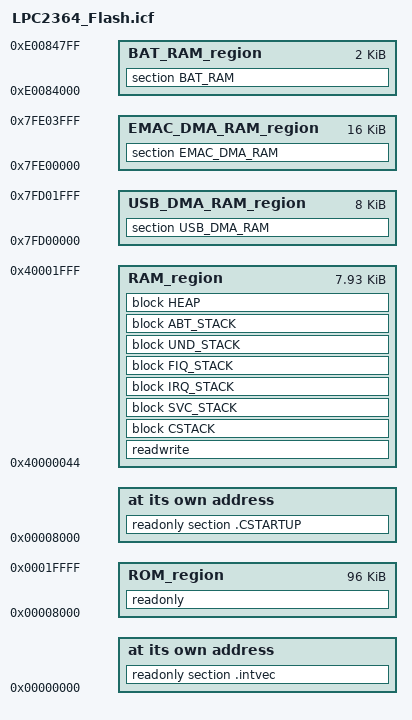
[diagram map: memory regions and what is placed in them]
/*
 * $Id$
 */

/*###ICF### Section handled by ICF editor, don't touch! ****/
/*-Editor annotation file-*/
/* IcfEditorFile="$TOOLKIT_DIR$\config\ide\IcfEditor\a_v1_0.xml" */

/*-Specials-*/
define symbol __ICFEDIT_intvec_start__   = 0x00000000;
define symbol __ICFEDIT_cstartup_start__ = 0x00008000;


/*-Memory Regions-*/
define symbol __ICFEDIT_region_ROM_start__ = 0x00008000;
define symbol __ICFEDIT_region_ROM_end__   = 0x0001FFFF;
define symbol __ICFEDIT_region_RAM_start__ = 0x40000044;
define symbol __ICFEDIT_region_RAM_end__   = 0x40001FFF;


/*-USB Memory Regions-*/
define symbol __region_USB_DMA_RAM_start__ = 0x7FD00000;
define symbol __region_USB_DMA_RAM_end__   = 0x7FD01FFF;

/*-EMAC Memory Regions-*/
define symbol __region_EMAC_DMA_RAM_start__ = 0x7FE00000;
define symbol __region_EMAC_DMA_RAM_end__   = 0x7FE03FFF;

/*-BATRAM Memory Regions-*/
define symbol __region_BAT_RAM_start__ = 0xE0084000;
define symbol __region_BAT_RAM_end__   = 0xE00847FF;


/*-Sizes-*/
define symbol __ICFEDIT_size_cstack__   = 0x900;
define symbol __ICFEDIT_size_svcstack__ = 0x10;
define symbol __ICFEDIT_size_irqstack__ = 0x200;
define symbol __ICFEDIT_size_fiqstack__ = 0x40;
define symbol __ICFEDIT_size_undstack__ = 0x10;
define symbol __ICFEDIT_size_abtstack__ = 0x10;
define symbol __ICFEDIT_size_heap__     = 0x100;
/**** End of ICF editor section. ###ICF###*/


define memory mem with size = 4G;
define region ROM_region = mem:[from __ICFEDIT_region_ROM_start__  to __ICFEDIT_region_ROM_end__];
define region RAM_region = mem:[from __ICFEDIT_region_RAM_start__  to __ICFEDIT_region_RAM_end__];


define region USB_DMA_RAM_region = mem:[from __region_USB_DMA_RAM_start__    to __region_USB_DMA_RAM_end__];
define region EMAC_DMA_RAM_region = mem:[from __region_EMAC_DMA_RAM_start__  to __region_EMAC_DMA_RAM_end__];
define region BAT_RAM_region = mem:[from __region_BAT_RAM_start__  to __region_BAT_RAM_end__];

define block CSTACK    with alignment = 8, size = __ICFEDIT_size_cstack__   { };
define block SVC_STACK with alignment = 8, size = __ICFEDIT_size_svcstack__ { };
define block IRQ_STACK with alignment = 8, size = __ICFEDIT_size_irqstack__ { };
define block FIQ_STACK with alignment = 8, size = __ICFEDIT_size_fiqstack__ { };
define block UND_STACK with alignment = 8, size = __ICFEDIT_size_undstack__ { };
define block ABT_STACK with alignment = 8, size = __ICFEDIT_size_abtstack__ { };
define block HEAP      with alignment = 8, size = __ICFEDIT_size_heap__     { };


/* Place code at a fixed address */
place at address mem:__ICFEDIT_intvec_start__ { readonly section .intvec };
place at address mem:__ICFEDIT_cstartup_start__ { readonly section .CSTARTUP };


initialize by copy { readwrite };
do not initialize  { section .noinit };

do not initialize  { section USB_DMA_RAM };
do not initialize  { section EMAC_DMA_RAM };
do not initialize  { section BAT_RAM };

place in ROM_region   { readonly };
place in RAM_region   { readwrite,
                        block CSTACK, block SVC_STACK, block IRQ_STACK, block FIQ_STACK,
                        block UND_STACK, block ABT_STACK, block HEAP };

place in USB_DMA_RAM_region   { section USB_DMA_RAM };
place in EMAC_DMA_RAM_region  { section EMAC_DMA_RAM };
place in BAT_RAM_region  { section BAT_RAM };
